# AT91SAM9M11 register map
Vendor: Atmel; Series: SAM9M; File version: 20130207
Registers are 32-bit, read-write, reset 0x0 unless marked. A register's access mark holds for its fields unless they carry their own. Offsets are from the block's base; [hi:lo] are bit positions; {n}, {i} and the like mark numbered series.

## SMC — Static Memory Controller
Base 0xFFFFE800; register names take the prefix SMC_
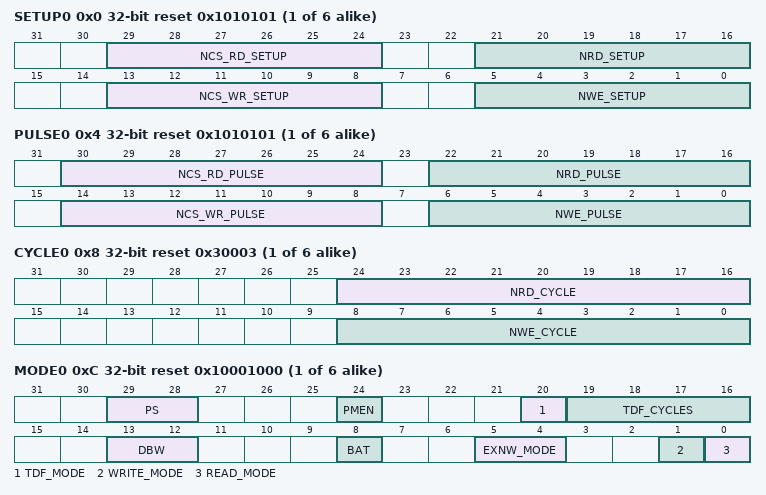
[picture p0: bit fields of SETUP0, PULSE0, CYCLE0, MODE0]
{0x0+0x10*i} SETUP{i} reset 0x1010101 (i=0..5) — SMC Setup Register (CS_number = {i})
  [29:24] NCS_RD_SETUP — NCS Setup Length in READ Access
  [21:16] NRD_SETUP — NRD Setup Length
  [13:8] NCS_WR_SETUP — NCS Setup Length in WRITE Access
  [5:0] NWE_SETUP — NWE Setup Length
{0x4+0x10*i} PULSE{i} reset 0x1010101 (i=0..5) — SMC Pulse Register (CS_number = {i})
  [30:24] NCS_RD_PULSE — NCS Pulse Length in READ Access
  [22:16] NRD_PULSE — NRD Pulse Length
  [14:8] NCS_WR_PULSE — NCS Pulse Length in WRITE Access
  [6:0] NWE_PULSE — NWE Pulse Length
{0x8+0x10*i} CYCLE{i} reset 0x30003 (i=0..5) — SMC Cycle Register (CS_number = {i})
  [24:16] NRD_CYCLE — Total Read Cycle Length
  [8:0] NWE_CYCLE — Total Write Cycle Length
{0xC+0x10*i} MODE{i} reset 0x10001000 (i=0..5) — SMC Mode Register (CS_number = {i})
  [29:28] PS — Page Size
  [24] PMEN — Page Mode Enabled
  [20] TDF_MODE — TDF Optimization
  [19:16] TDF_CYCLES — Data Float Time
  [13:12] DBW — Data Bus Width
  [8] BAT — Byte Access Type
  [5:4] EXNW_MODE — NWAIT Mode
  [1] WRITE_MODE
  [0] READ_MODE
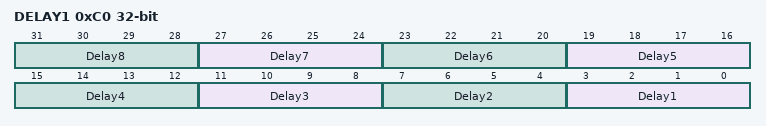
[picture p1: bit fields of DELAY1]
0xC0 DELAY1 — SMC Delay on I/O
  [4n-1:4n-4] Delay{n} (n=1..8)
{0xBC+4i} DELAY{i} (i=2..8) — SMC Delay on I/O

## MATRIX — AHB Bus Matrix
Base 0xFFFFEA00; register names take the prefix MATRIX_
{0x0+4i} MCFG[{i}] (i=0..10) reset not defined — Master Configuration Register
  [2:0] ULBT — Undefined Length Burst Type
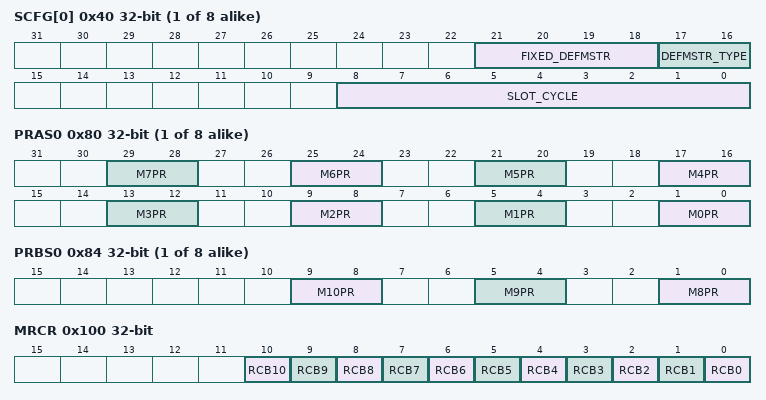
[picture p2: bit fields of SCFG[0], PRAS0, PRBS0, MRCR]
{0x40+4i} SCFG[{i}] (i=0..7) reset not defined — Slave Configuration Register
  [21:18] FIXED_DEFMSTR — Fixed Default Master
  [17:16] DEFMSTR_TYPE — Default Master Type
  [8:0] SLOT_CYCLE — Maximum Bus Grant Duration for Masters
{0x80+8i} PRAS{i} (i=0..7) — Priority Register A for Slave {i}
  [4n+1:4n] M{n}PR (n=0..7) — Master {n} Priority
{0x84+8i} PRBS{i} (i=0..7) — Priority Register B for Slave {i}
  [9:8] M10PR — Master 10 Priority
  [5:4] M9PR — Master 9 Priority
  [1:0] M8PR — Master 8 Priority
0x100 MRCR — Master Remap Control Register
  [n] RCB{n} (n=0..10)
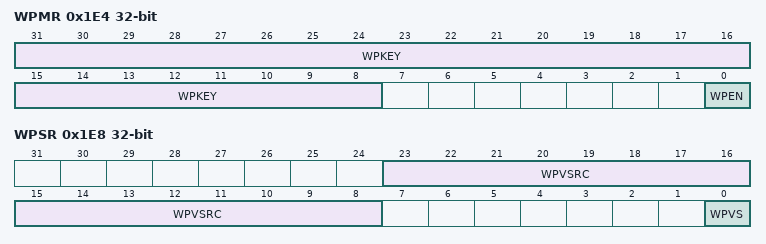
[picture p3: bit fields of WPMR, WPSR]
0x1E4 WPMR — Write Protect Mode Register
  [31:8] WPKEY — Write Protect KEY (Write-only)
  [0] WPEN — Write Protect ENable
0x1E8 WPSR ro — Write Protect Status Register
  [23:8] WPVSRC — Write Protect Violation Source
  [0] WPVS — Write Protect Violation Status

## AIC — Advanced Interrupt Controller
Base 0xFFFFF000; register names take the prefix AIC_
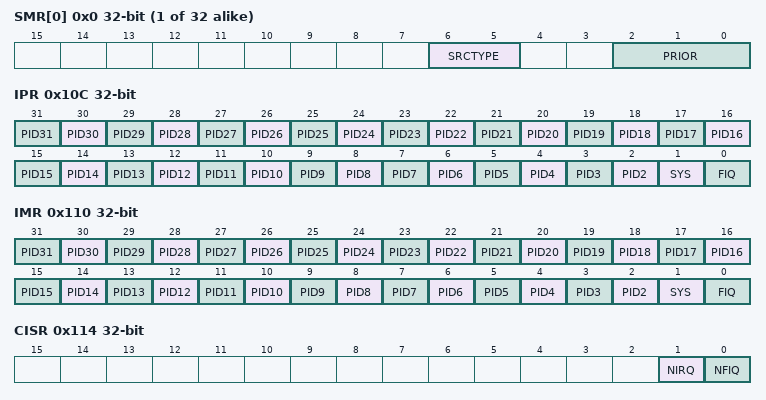
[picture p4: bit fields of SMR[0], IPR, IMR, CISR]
{0x0+4i} SMR[{i}] (i=0..31) reset not defined — Source Mode Register
  [6:5] SRCTYPE — Interrupt Source Type
  [2:0] PRIOR — Priority Level
{0x80+4i} SVR[{i}] (i=0..31) reset not defined — Source Vector Register
  [31:0] VECTOR — Source Vector
0x100 IVR ro — Interrupt Vector Register
  [31:0] IRQV
0x104 FVR ro — FIQ Interrupt Vector Register
  [31:0] FIQV — FIQ Vector Register
0x108 ISR ro — Interrupt Status Register
  [4:0] IRQID — Current Interrupt Identifier
0x10C IPR ro — Interrupt Pending Register
  [n] PID{n} (n=2..31) — Interrupt Pending
  [1] SYS — Interrupt Pending
  [0] FIQ — Interrupt Pending
0x110 IMR ro — Interrupt Mask Register
  [n] PID{n} (n=2..31) — Interrupt Mask
  [1] SYS — Interrupt Mask
  [0] FIQ — Interrupt Mask
0x114 CISR ro — Core Interrupt Status Register
  [1] NIRQ — NIRQ Status
  [0] NFIQ — NFIQ Status
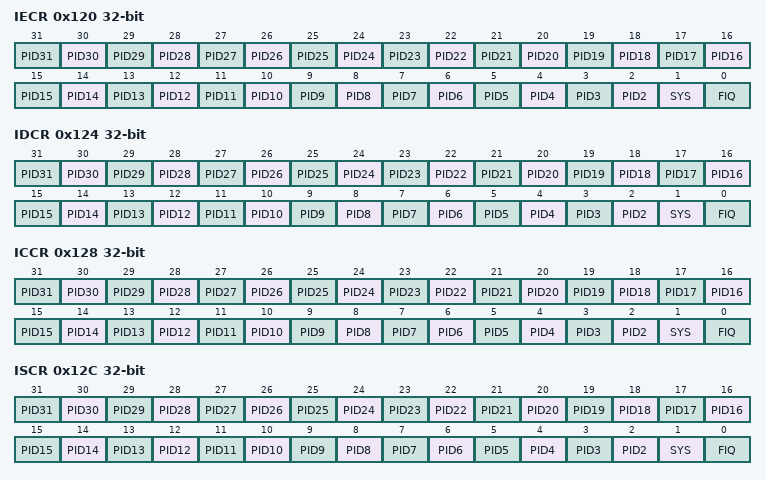
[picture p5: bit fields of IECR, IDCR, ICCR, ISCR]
0x120 IECR wo reset not defined — Interrupt Enable Command Register
  [n] PID{n} (n=2..31) — Interrupt Enable
  [1] SYS — Interrupt Enable
  [0] FIQ — Interrupt Enable
0x124 IDCR wo reset not defined — Interrupt Disable Command Register
  [n] PID{n} (n=2..31) — Interrupt Disable
  [1] SYS — Interrupt Disable
  [0] FIQ — Interrupt Disable
0x128 ICCR wo reset not defined — Interrupt Clear Command Register
  [n] PID{n} (n=2..31) — Interrupt Clear
  [1] SYS — Interrupt Clear
  [0] FIQ — Interrupt Clear
0x12C ISCR wo reset not defined — Interrupt Set Command Register
  [n] PID{n} (n=2..31) — Interrupt Set
  [1] SYS — Interrupt Set
  [0] FIQ — Interrupt Set
0x130 EOICR wo reset not defined — End of Interrupt Command Register
0x134 SPU — Spurious Interrupt Vector Register
  [31:0] SIVR
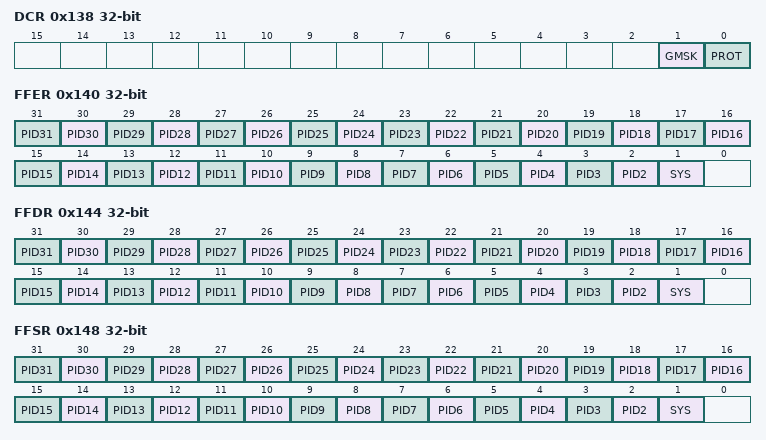
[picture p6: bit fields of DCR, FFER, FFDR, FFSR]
0x138 DCR — Debug Control Register
  [1] GMSK — General Mask
  [0] PROT — Protection Mode
0x140 FFER wo reset not defined — Fast Forcing Enable Register
  [n] PID{n} (n=2..31) — Fast Forcing Enable
  [1] SYS — Fast Forcing Enable
0x144 FFDR wo reset not defined — Fast Forcing Disable Register
  [n] PID{n} (n=2..31) — Fast Forcing Disable
  [1] SYS — Fast Forcing Disable
0x148 FFSR ro — Fast Forcing Status Register
  [n] PID{n} (n=2..31) — Fast Forcing Status
  [1] SYS — Fast Forcing Status
